# D1H.pdf register map
Vendor: Allwinner; Series: D1H.pdf; File version: 0.1
CPU: XuanTie C906 RISC-V CPU 0, little endian, MPU, FPU, double-precision FPU, 0 interrupt priority bits
Registers are 32-bit, read-write, reset 0x0 unless marked. A register's access mark holds for its fields unless they carry their own. Offsets are from the block's base; [hi:lo] are bit positions; 'fields as' and 'values as' point back to an identical list.

## CCU (part 1 of 2)
Base 0x02001000
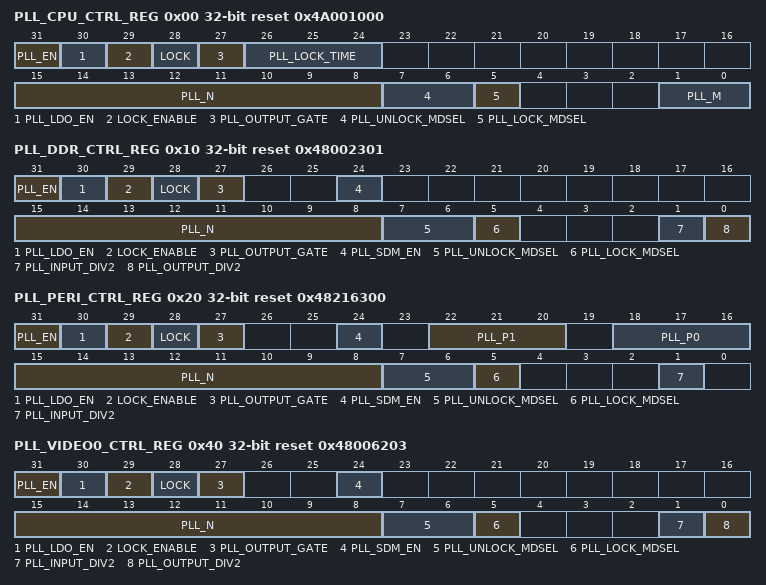
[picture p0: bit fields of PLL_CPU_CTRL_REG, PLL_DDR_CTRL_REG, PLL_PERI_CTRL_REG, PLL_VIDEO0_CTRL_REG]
0x00 PLL_CPU_CTRL_REG reset 0x4A001000 — PLL_CPU Control Register
  [31] PLL_EN — PLL Enable 0: Disable 1: Enable PLL_CPU= InputFreq*N.
    0=Disable; 1=Enable PLL_CPU= InputFreq*N
  [30] PLL_LDO_EN — LDO Enable 0: Disable 1: Enable
    0=Disable; 1=Enable
  [29] LOCK_ENABLE — Lock Enable 0: Disable 1: Enable
    0=Disable; 1=Enable
  [28] LOCK ro — PLL Lock Status 0: Unlocked 1: Locked (It indicates that the PLL has been stable.)
    0=Unlocked; 1=Locked (It indicates that the PLL has been stable.)
  [27] PLL_OUTPUT_GATE — PLL Output Gating Enable 0: Disable 1: Enable The bit is used to control the output enable of the PLL.
    0=Disable; 1=Enable The bit is used to control the output enable of the PLL
  [26:24] PLL_LOCK_TIME — PLL Lock Time The bit indicates the step amplitude from one frequency to another.
  [15:8] PLL_N — PLL N N= PLL_N +1 PLL_N is from 0 to 254. In application, PLL_N shall be more than or equal to 12.
  [7:6] PLL_UNLOCK_MDSEL — PLL Unlock Level 00: 21-29 Clock Cycles 01: 22-28 Clock Cycles 1X: 20-30 Clock Cycles
    0=_21_minus_29 (21-29 Clock Cycles); 1=_22_minus_28 (22-28 Clock Cycles)
  [5] PLL_LOCK_MDSEL — PLL Lock Level 0: 24-26 Clock Cycles 1: 23-27 Clock Cycles
    0=_24_minus_26 (24-26 Clock Cycles); 1=_23_minus_27 (23-27 Clock Cycles)
  [1:0] PLL_M — PLL_M M = PLL_FACTOR_M + 1 PLL_FACTOR_M is from 0 to 3.
0x10 PLL_DDR_CTRL_REG reset 0x48002301 — PLL_DDR Control Register
  [31] PLL_EN — 0: Disable 1: Enable PLL_DDR = InputFreq*N/M1/M0.
    0=Disable; 1=Enable PLL_DDR = InputFreq*N/M1/M0
  [30] PLL_LDO_EN — LDO ENABLE 0: Disable 1: Enable
    0=Disable; 1=Enable
  [29] LOCK_ENABLE — Lock Enable 0: Disable 1: Enable
    0=Disable; 1=Enable
  [28] LOCK ro — PLL Lock 0: Unlocked 1: Locked (It indicates that the PLL has been stable.)
    values as PLL_CPU_CTRL_REG.LOCK
  [27] PLL_OUTPUT_GATE — PLL Output Gating Enable 0: Disable 1: Enable The bit is used to control the output enable of the PLL.
    values as PLL_CPU_CTRL_REG.PLL_OUTPUT_GATE
  [24] PLL_SDM_EN — PLL SDM Enable 0: Disable 1: Enable
    0=Disable; 1=Enable
  [15:8] PLL_N — PLL N N= PLL_N +1 PLL_N is from 0 to 254. In application, PLL_N shall be more than or equal to 12.
  [7:6] PLL_UNLOCK_MDSEL — PLL Unlock Level 00: 21-29 Clock Cycles 01: 22-28 Clock Cycles 1X: 20-30 Clock Cycles
    values as PLL_CPU_CTRL_REG.PLL_UNLOCK_MDSEL
  [5] PLL_LOCK_MDSEL — PLL Lock Level 0: 24-26 Clock Cycles 1: 23-27 Clock Cycles
    values as PLL_CPU_CTRL_REG.PLL_LOCK_MDSEL
  [1] PLL_INPUT_DIV2 — PLL Input Div M1 M1=PLL_INPUT_DIV2 + 1 PLL_INPUT_DIV2 is from 0 to 1.
  [0] PLL_OUTPUT_DIV2 — PLL Output Div M0 M0=PLL_OUTPUT_DIV2 + 1 PLL_OUTPUT_DIV2 is from 0 to 1.
0x20 PLL_PERI_CTRL_REG reset 0x48216300 — PLL_PERI Control Register
  [31] PLL_EN — PLL Enable 0: Disable 1: Enable PLL_PERI(2X) = 24 MHz*N/M/P0 PLL_PERI(1X) = 24 MHz*N/M/P0/2 PLL_PERI(800M) = 24 MHz*N/M/P1. When the crystal oscillator is 24 MHz, the default frequency of PLL_PERI(2X) is 1.2 GHz, the default frequency of PLL_PERI(1X) is 600 MHz, and the default frequency of PLL_PERI(800M) is 800 MHz.
    0=Disable; 1=Enable PLL_PERI(2X) = 24 MHz*N/M/P0 PLL_PERI(1X) = 24 MHz*N/M/P0/2 PLL_PERI(800M) = 24 MHz*N/M/P1. When the crystal oscillator is 24 MHz, the default frequency of PLL_PERI(2X) is 1.2 GHz, the default frequency of PLL_PERI(1X) is 600 MHz, and the default frequency of PLL_PERI(800M) is 800 MHz.
  [30] PLL_LDO_EN — LDO Enable 0: Disable 1: Enable
    0=Disable; 1=Enable
  [29] LOCK_ENABLE — Lock Enable 0: Disable 1: Enable
    0=Disable; 1=Enable
  [28] LOCK ro — PLL Lock 0: Unlocked 1: Locked (It indicates that the PLL has been stable.)
    values as PLL_CPU_CTRL_REG.LOCK
  [27] PLL_OUTPUT_GATE — PLL Output Gating Enable 0: Disable 1: Enable The bit is used to control the output enable of PLL.
    0=Disable; 1=Enable The bit is used to control the output enable of PLL
  [24] PLL_SDM_EN — PLL SDM Enable 0: Disable 1: Enable Enable spread spectrum and decimal division.
    0=Disable; 1=Enable Enable spread spectrum and decimal division
  [22:20] PLL_P1 — PLL Output Div P1 P1=PLL_OUTPUT_DIV_P1 + 1 PLL_OUTPUT_DIV_P1 is from 0 to 7.
  [18:16] PLL_P0 — PLL Output Div P0 P0=PLL_OUTPUT_DIV_P0 + 1 PLL_OUTPUT_DIV_P0 is from 0 to 7.
  [15:8] PLL_N — PLL N N= PLL_N +1 PLL_N is from 0 to 254. In application, PLL_N shall be more than or equal to 12.
  [7:6] PLL_UNLOCK_MDSEL — PLL Unlock Level 00: 21-29 Clock Cycles 01: 22-28 Clock Cycles 1X: 20-30 Clock Cycles
    values as PLL_CPU_CTRL_REG.PLL_UNLOCK_MDSEL
  [5] PLL_LOCK_MDSEL — PLL Lock Level 0: 24-26 Clock Cycles 1: 23-27 Clock Cycles
    values as PLL_CPU_CTRL_REG.PLL_LOCK_MDSEL
  [1] PLL_INPUT_DIV2 — PLL Input Div M M1=PLL_INPUT_DIV2 + 1 PLL_INPUT_DIV2 is from 0 to 1.
0x40 PLL_VIDEO0_CTRL_REG reset 0x48006203 — PLL_VIDEO0 Control Register
  [31] PLL_EN — PLL Enable 0: Disable 1: Enable For application, PLL_VIDEO0(4X)=InputFreq *N/M. PLL_VIDEO0(2X)= InputFreq *N/M/2. PLL_VIDEO0(1X)= InputFreq *N/M/4. When the HOSC is 24 MHz, the default frequency of PLL_VIDEO0(4X) is 1188 MHz.
    0=Disable; 1=Enable For application, PLL_VIDEO0(4X)=InputFreq *N/M. PLL_VIDEO0(2X)= InputFreq *N/M/2. PLL_VIDEO0(1X)= InputFreq *N/M/4. When the HOSC is 24 MHz, the default frequency of PLL_VIDEO0(4X) is 1188 MHz.
  [30] PLL_LDO_EN — LDO Enable 0: Disable 1: Enable
    0=Disable; 1=Enable
  [29] LOCK_ENABLE — Lock Enable 0: Disable 1: Enable
    0=Disable; 1=Enable
  [28] LOCK ro — PLL Lock 0: Unlocked 1: Locked (It indicates that the PLL has been stable.)
    values as PLL_CPU_CTRL_REG.LOCK
  [27] PLL_OUTPUT_GATE — PLL Output Gating Enable 0: Disable 1: Enable The bit is used to control the output enable of PLL.
    values as PLL_PERI_CTRL_REG.PLL_OUTPUT_GATE
  [24] PLL_SDM_EN — PLL SDM Enable 0: Disable 1: Enable
    0=Disable; 1=Enable
  [15:8] PLL_N — PLL N N= PLL_N +1 PLL_N is from 0 to 254. In application, PLL_N shall be more than or equal to 12.
  [7:6] PLL_UNLOCK_MDSEL — PLL Unlock Level 00: 21-29 Clock Cycles 01: 22-28 Clock Cycles 1X: 20-30 Clock Cycles
    values as PLL_CPU_CTRL_REG.PLL_UNLOCK_MDSEL
  [5] PLL_LOCK_MDSEL — PLL Lock Level 0: 24-26 Clock Cycles 1: 23-27 Clock Cycles
    values as PLL_CPU_CTRL_REG.PLL_LOCK_MDSEL
  [1] PLL_INPUT_DIV2 — PLL Input Div M M1=PLL_INPUT_DIV_M + 1 PLL_INPUT_DIV_M is from 0 to 1.
  [0] PLL_OUTPUT_DIV2 — PLL Output Div D (The factor is only for testing) M0=PLL_OUTPUT_DIV_D + 1 PLL_OUTPUT_DIV_D is from 0 to 1. For test, PLL_VIDEO0(4X) =24MHz*N/M/D
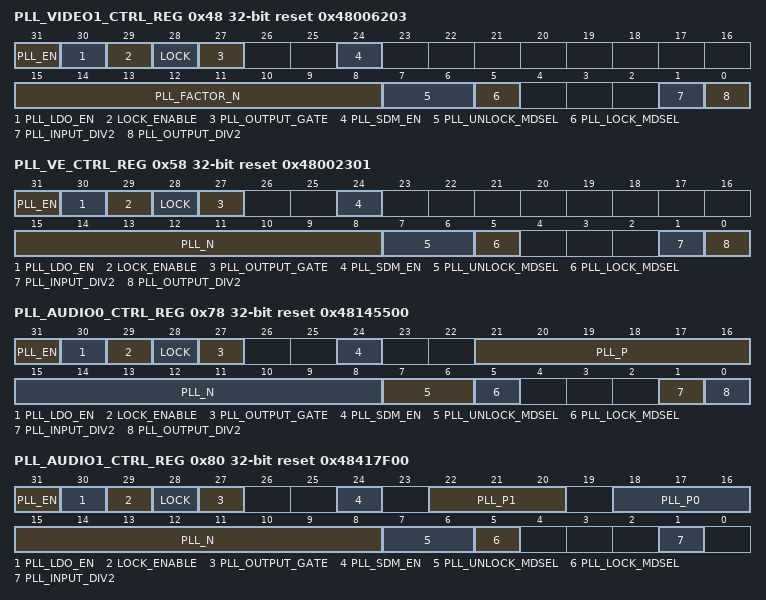
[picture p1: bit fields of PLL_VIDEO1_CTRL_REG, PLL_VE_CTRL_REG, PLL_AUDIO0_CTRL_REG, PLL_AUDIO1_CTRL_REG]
0x48 PLL_VIDEO1_CTRL_REG reset 0x48006203 — PLL_VIDEO1 Control Register
  [31] PLL_EN — PLL Enable 0: Disable 1: Enable For application, PLL_VIDEO1(4X)=InputFreq *N/M. PLL_VIDEO1(2X)= InputFreq *N/M/2. PLL_VIDEO1(1X)= InputFreq *N/M/4. When the HOSC is 24 MHz, the default frequency of PLL_VIDEO1(4X) is 1188 MHz.
    0=Disable; 1=Enable For application, PLL_VIDEO1(4X)=InputFreq *N/M. PLL_VIDEO1(2X)= InputFreq *N/M/2. PLL_VIDEO1(1X)= InputFreq *N/M/4. When the HOSC is 24 MHz, the default frequency of PLL_VIDEO1(4X) is 1188 MHz.
  [30] PLL_LDO_EN — LDO Enable 0: Disable 1: Enable
    0=Disable; 1=Enable
  [29] LOCK_ENABLE — Lock Enable 0: Disable 1: Enable
    0=Disable; 1=Enable
  [28] LOCK ro — PLL Lock 0: Unlocked 1: Locked (It indicates that the PLL has been stable.)
    values as PLL_CPU_CTRL_REG.LOCK
  [27] PLL_OUTPUT_GATE — PLL Output Gating Enable 0: Disable 1: Enable The bit is used to control the output enable of PLL.
    values as PLL_PERI_CTRL_REG.PLL_OUTPUT_GATE
  [24] PLL_SDM_EN — PLL SDM Enable 0: Disable 1: Enable
    0=Disable; 1=Enable
  [15:8] PLL_FACTOR_N — PLL FACTOR N N= PLL_FACTOR_N +1 PLL_FACTOR_N is from 0 to 254. In application, PLL_FACTOR_N shall be more than or equal to 12.
  [7:6] PLL_UNLOCK_MDSEL — PLL Unlock Level 00: 21-29 Clock Cycles 01: 22-28 Clock Cycles 1X: 20-30 Clock Cycles
    values as PLL_CPU_CTRL_REG.PLL_UNLOCK_MDSEL
  [5] PLL_LOCK_MDSEL — PLL Lock Level 0: 24-26 Clock Cycles 1: 23-27 Clock Cycles
    values as PLL_CPU_CTRL_REG.PLL_LOCK_MDSEL
  [1] PLL_INPUT_DIV2 — PLL Input Div M M1=PLL_INPUT_DIV_M + 1 PLL_INPUT_DIV_M is from 0 to 1.
  [0] PLL_OUTPUT_DIV2 — PLL Output Div D.(The factor is only for testing) M0=PLL_OUTPUT_DIV_D + 1 PLL_OUTPUT_DIV_D is from 0 to 1. For test, PLL_VIDEO1(4X) =24MHz*N/M/D
0x58 PLL_VE_CTRL_REG reset 0x48002301 — PLL_VE Control Register
  [31] PLL_EN — PLL Enable 0: Disable 1: Enable PLL_VE = InputFreq*N/M1/M0. When the HOSC is 24 MHz, the default frequency of PLL_VE is 432 MHz.
    0=Disable; 1=Enable PLL_VE = InputFreq*N/M1/M0. When the HOSC is 24 MHz, the default frequency of PLL_VE is 432 MHz.
  [30] PLL_LDO_EN — LDO Enable 0: Disable 1: Enable
    0=Disable; 1=Enable
  [29] LOCK_ENABLE — Lock Enable 0: Disable 1: Enable
    0=Disable; 1=Enable
  [28] LOCK ro — PLL Lock 0: Unlocked 1: Locked (It indicates that the PLL has been stable.)
    values as PLL_CPU_CTRL_REG.LOCK
  [27] PLL_OUTPUT_GATE — PLL Output Gating Enable 0: Disable 1: Enable The bit is used to control the output enable of PLL.
    values as PLL_PERI_CTRL_REG.PLL_OUTPUT_GATE
  [24] PLL_SDM_EN — PLL SDM Enable 0: Disable 1: Enable
    0=Disable; 1=Enable
  [15:8] PLL_N — PLL N N= PLL_N +1 PLL_N is from 0 to 254. In application, PLL_N shall be more than or equal to 12.
  [7:6] PLL_UNLOCK_MDSEL — PLL Unlock Level 00: 21-29 Clock Cycles 01: 22-28 Clock Cycles 1X: 20-30 Clock Cycles
    values as PLL_CPU_CTRL_REG.PLL_UNLOCK_MDSEL
  [5] PLL_LOCK_MDSEL — PLL Lock Level 0: 24-26 Clock Cycles 1: 23-27 Clock Cycles
    values as PLL_CPU_CTRL_REG.PLL_LOCK_MDSEL
  [1] PLL_INPUT_DIV2 — PLL Input Div M1 M1=PLL_INPUT_DIV2 + 1 PLL_INPUT_DIV2 is from 0 to 1.
  [0] PLL_OUTPUT_DIV2 — PLL Output Div M0 M0=PLL_OUTPUT_DIV2 + 1 PLL_OUTPUT_DIV2 is from 0 to 1.
0x78 PLL_AUDIO0_CTRL_REG reset 0x48145500 — PLL_AUDIO0 Control Register
  [31] PLL_EN — PLL Enable 0: Disable 1: Enable PLL_AUDIO0(4X) = 24MHz*N/M1/M0/P PLL_AUDIO0(2X) = (24MHz*N/M1/M0)/P/2 PLL_AUDIO0(1X) = (24MHz*N/M1/M0)/P/4 The working frequency range of 24MHz*N/M0/M1 is from 180 MHz to 3.0 GHz. The default frequency of PLL_AUDIO0(1X) is 24.5714 MHz.
    0=Disable; 1=Enable PLL_AUDIO0(4X) = 24MHz*N/M1/M0/P PLL_AUDIO0(2X) = (24MHz*N/M1/M0)/P/2 PLL_AUDIO0(1X) = (24MHz*N/M1/M0)/P/4 The working frequency range of 24MHz*N/M0/M1 is from 180 MHz to 3.0 GHz. The default frequency of PLL_AUDIO0(1X) is 24.5714 MHz.
  [30] PLL_LDO_EN — LDO Enable 0: Disable 1: Enable
    0=Disable; 1=Enable
  [29] LOCK_ENABLE — Lock Enable 0: Disable 1: Enable
    0=Disable; 1=Enable
  [28] LOCK ro — PLL Lock 0: Unlocked 1: Locked (It indicates that the PLL has been stable.)
    values as PLL_CPU_CTRL_REG.LOCK
  [27] PLL_OUTPUT_GATE — 0: Disable 1: Enable The bit is used to control the output enable of PLL.
    values as PLL_PERI_CTRL_REG.PLL_OUTPUT_GATE
  [24] PLL_SDM_EN — PLL SDM Enable 0: Disable 1: Enable Enable spread spectrum and decimal division.
    values as PLL_PERI_CTRL_REG.PLL_SDM_EN
  [21:16] PLL_P — PLL Post-div P P= PLL_POST_DIV_P +1 PLL_POST_DIV_P is from 0 to 63.
  [15:8] PLL_N — PLL N N= PLL_N +1 PLL_N is from 0 to 254. In application, PLL_N shall be more than or equal to 12.
  [7:6] PLL_UNLOCK_MDSEL — PLL Unlock Level 00: 21-29 Clock Cycles 01: 22-28 Clock Cycles 1X: 20-30 Clock Cycles
    values as PLL_CPU_CTRL_REG.PLL_UNLOCK_MDSEL
  [5] PLL_LOCK_MDSEL — PLL Lock Level 0: 24-26 Clock Cycles 1: 23-27 Clock Cycles
    values as PLL_CPU_CTRL_REG.PLL_LOCK_MDSEL
  [1] PLL_INPUT_DIV2 — PLL Input Div M1 M1=PLL_INPUT_DIV2 + 1 PLL_INPUT_DIV2 is from 0 to 1.
  [0] PLL_OUTPUT_DIV2 — PLL Output Div M0 M0=PLL_OUTPUT_DIV2 + 1 PLL_OUTPUT_DIV2 is from 0 to 1.
0x80 PLL_AUDIO1_CTRL_REG reset 0x48417F00 — PLL_AUDIO1 Control Register
  [31] PLL_EN — PLL Enable 0: Disable 1: Enable PLL_AUDIO1 = 24MHz*N/M PLL_AUDIO1(DIV2) = 24MHz*N/M/P0 PLL_AUDIO1(DIV5) = 24MHz*N/M/P1 The working frequency range of 24 MHz/M*N is from 180 MHz to 3.5 GHz. The default frequency of PLL_AUDIO1 is 3072 MHz. The default frequency of PLL_AUDIO1(DIV2) is 1536 MHz. The default frequency of PLL_AUDIO1(DIV5) is 614.4 MHz (24.576 MHz*25).
    0=Disable; 1=Enable PLL_AUDIO1 = 24MHz*N/M PLL_AUDIO1(DIV2) = 24MHz*N/M/P0 PLL_AUDIO1(DIV5) = 24MHz*N/M/P1 The working frequency range of 24 MHz/M*N is from 180 MHz to 3.5 GHz. The default frequency of PLL_AUDIO1 is 3072 MHz. The default frequency of PLL_AUDIO1(DIV2) is 1536 MHz. The default frequency of PLL_AUDIO1(DIV5) is 614.4 MHz (24.576 MHz*25).
  [30] PLL_LDO_EN — LDO Enable 0: Disable 1: Enable
    0=Disable; 1=Enable
  [29] LOCK_ENABLE — Lock Enable 0: Disable 1: Enable
    0=Disable; 1=Enable
  [28] LOCK ro — 0: Unlocked 1: Locked (It indicates that the PLL has been stable.)
    values as PLL_CPU_CTRL_REG.LOCK
  [27] PLL_OUTPUT_GATE — 0: Disable 1: Enable The bit is used to control the output enable of PLL.
    values as PLL_PERI_CTRL_REG.PLL_OUTPUT_GATE
  [24] PLL_SDM_EN — 0: Disable 1: Enable Enable spread spectrum and decimal division.
    values as PLL_PERI_CTRL_REG.PLL_SDM_EN
  [22:20] PLL_P1 — PLL Output Div P1 P1=PLL_OUTPUT_DIV_P1 + 1 PLL_OUTPUT_DIV_P1 is from 0 to 7.
  [18:16] PLL_P0 — PLL Output Div P0 P0=PLL_OUTPUT_DIV_P0 + 1 PLL_OUTPUT_DIV_P0 is from 0 to 7.
  [15:8] PLL_N — PLL N N= PLL_N +1 PLL_N is from 0 to 254. In application, PLL_N shall be more than or equal to 12.
  [7:6] PLL_UNLOCK_MDSEL — PLL Unlock Level 00: 21-29 Clock Cycles 01: 22-28 Clock Cycles 1X: 20-30 Clock Cycles
    values as PLL_CPU_CTRL_REG.PLL_UNLOCK_MDSEL
  [5] PLL_LOCK_MDSEL — PLL Lock Level 0: 24-26 Clock Cycles 1: 23-27 Clock Cycles
    values as PLL_CPU_CTRL_REG.PLL_LOCK_MDSEL
  [1] PLL_INPUT_DIV2 — PLL Input Div M M=PLL_INPUT_DIV_M + 1 PLL_INPUT_DIV_M is from 0 to 1.
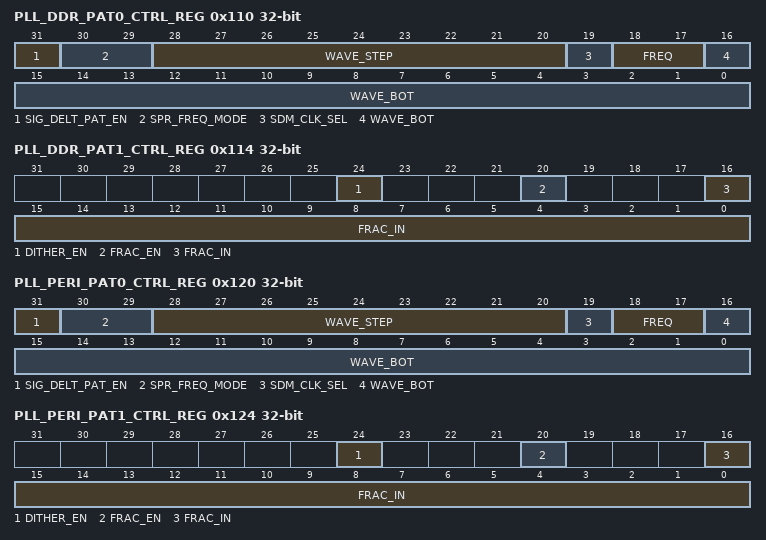
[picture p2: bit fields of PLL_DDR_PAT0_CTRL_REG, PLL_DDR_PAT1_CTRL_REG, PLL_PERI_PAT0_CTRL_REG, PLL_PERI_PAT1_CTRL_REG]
0x110 PLL_DDR_PAT0_CTRL_REG — PLL_DDR Pattern0 Control Register
  [31] SIG_DELT_PAT_EN — Sigma-Delta Pattern Enable
  [30:29] SPR_FREQ_MODE — Spread Frequency Mode 00: DC=0 01: DC=1 10: Triangular(1-bit) 11: Triangular(n-bit)
    0=DC_equals_0 (DC=0); 1=DC_equals_1 (DC=1); 2=Triangular_openingparen_1_bit_closingparen_ (Triangular(1-bit)); 3=Triangular_openingparen_n_bit_closingparen_ (Triangular(n-bit))
  [28:20] WAVE_STEP
  [19] SDM_CLK_SEL — SDM Clock Select 0: 24 MHz 1: 12 MHz
    0=24 MHz; 1=12 MHz
  [18:17] FREQ — Frequency 00: 31.5 kHz 01: 32 kHz 10: 32.5 kHz 11: 33 kHz
    0=_31_point_5_kHz (31.5 kHz); 1=_32_kHz; 2=_32_point_5_kHz (32.5 kHz); 3=_33_kHz
  [16:0] WAVE_BOT — Wave Bottom
0x114 PLL_DDR_PAT1_CTRL_REG — PLL_DDR Pattern1 Control Register
  [24] DITHER_EN — Dither Enable
  [20] FRAC_EN — Fraction Enable
  [16:0] FRAC_IN — Fraction In
0x120 PLL_PERI_PAT0_CTRL_REG — PLL_PERI Pattern0 Control Register
  fields as PLL_DDR_PAT0_CTRL_REG
0x124 PLL_PERI_PAT1_CTRL_REG — PLL_PERI Pattern1 Control Register
  fields as PLL_DDR_PAT1_CTRL_REG
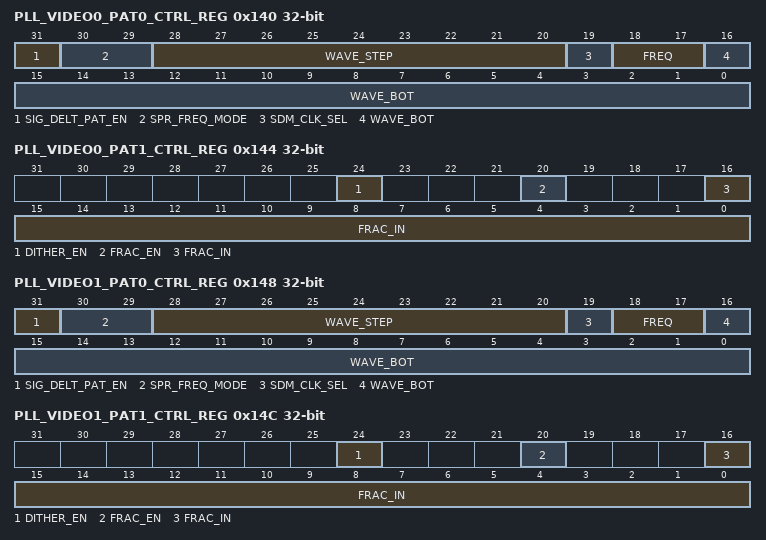
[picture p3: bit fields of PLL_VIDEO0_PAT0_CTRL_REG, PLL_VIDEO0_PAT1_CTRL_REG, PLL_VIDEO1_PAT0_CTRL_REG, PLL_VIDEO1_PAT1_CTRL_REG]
0x140 PLL_VIDEO0_PAT0_CTRL_REG — PLL_VIDEO0 Pattern0 Control Register
  fields as PLL_DDR_PAT0_CTRL_REG
0x144 PLL_VIDEO0_PAT1_CTRL_REG — PLL_VIDEO0 Pattern1 Control Register
  fields as PLL_DDR_PAT1_CTRL_REG
0x148 PLL_VIDEO1_PAT0_CTRL_REG — PLL_VIDEO1 Pattern0 Control Register
  fields as PLL_DDR_PAT0_CTRL_REG
0x14C PLL_VIDEO1_PAT1_CTRL_REG — PLL_VIDEO1 Pattern1 Control Register
  fields as PLL_DDR_PAT1_CTRL_REG
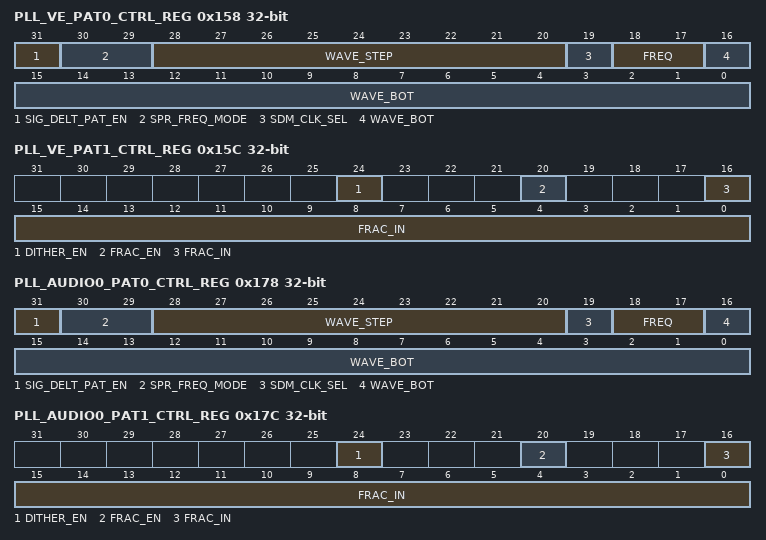
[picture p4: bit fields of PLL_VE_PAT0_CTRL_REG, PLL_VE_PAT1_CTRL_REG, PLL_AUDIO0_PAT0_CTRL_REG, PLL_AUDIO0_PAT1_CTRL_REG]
0x158 PLL_VE_PAT0_CTRL_REG — PLL_VE Pattern0 Control Register
  fields as PLL_DDR_PAT0_CTRL_REG
0x15C PLL_VE_PAT1_CTRL_REG — PLL_VE Pattern1 Control Register
  fields as PLL_DDR_PAT1_CTRL_REG
0x178 PLL_AUDIO0_PAT0_CTRL_REG — PLL_AUDIO0 Pattern0 Control Register
  fields as PLL_DDR_PAT0_CTRL_REG
0x17C PLL_AUDIO0_PAT1_CTRL_REG — PLL_AUDIO0 Pattern1 Control Register
  fields as PLL_DDR_PAT1_CTRL_REG
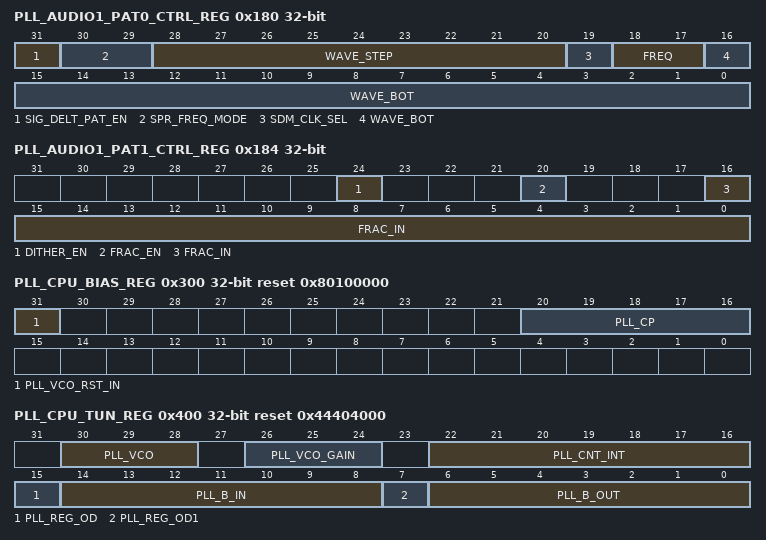
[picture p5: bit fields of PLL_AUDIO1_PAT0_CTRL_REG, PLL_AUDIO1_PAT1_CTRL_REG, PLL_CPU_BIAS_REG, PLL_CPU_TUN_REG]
0x180 PLL_AUDIO1_PAT0_CTRL_REG — PLL_AUDIO1 Pattern0 Control Register
  fields as PLL_DDR_PAT0_CTRL_REG
0x184 PLL_AUDIO1_PAT1_CTRL_REG — PLL_AUDIO1 Pattern1 Control Register
  fields as PLL_DDR_PAT1_CTRL_REG
0x300 PLL_CPU_BIAS_REG reset 0x80100000 — PLL_CPU Bias Register
  [31] PLL_VCO_RST_IN — VCO reset in
  [20:16] PLL_CP — PLL current bias control
0x310 PLL_DDR_BIAS_REG reset 0x30000 — PLL_DDR Bias Register
  [20:16] PLL_CP — PLL bias control
0x320 PLL_PERI_BIAS_REG reset 0x30000 — PLL_PERI Bias Register
  [20:16] PLL_CP — PLL bias control
0x340 PLL_VIDEO0_BIAS_REG reset 0x30000 — PLL_VIDEO0 Bias Register
  [20:16] PLL_CP — PLL bias control
0x348 PLL_VIDEO1_BIAS_REG reset 0x30000 — PLL_VIDEO1 Bias Register
  [20:16] PLL_CP — PLL bias control
0x358 PLL_VE_BIAS_REG reset 0x30000 — PLL_VE Bias Register
  [20:16] PLL_CP — PLL bias control
0x378 PLL_AUDIO0_BIAS_REG reset 0x30000 — PLL_AUDIO0 Bias Register
  [20:16] PLL_CP — PLL bias control
0x380 PLL_AUDIO1_BIAS_REG reset 0x30000 — PLL_AUDIO1 Bias Register
  [20:16] PLL_CP — PLL bias control
0x400 PLL_CPU_TUN_REG reset 0x44404000 — PLL_CPU Tuning Register
  [30:28] PLL_VCO — VCO range control
  [26:24] PLL_VCO_GAIN — KVCO gain control
  [22:16] PLL_CNT_INT — Counter initial control
  [15] PLL_REG_OD — PLL-REG-OD0 for verify
  [14:8] PLL_B_IN — PLL-B-IN [6:0] for verify
  [7] PLL_REG_OD1 — PLL-REG-OD1 for verify
  [6:0] PLL_B_OUT ro — PLL-B-OUT [6:0] for verify
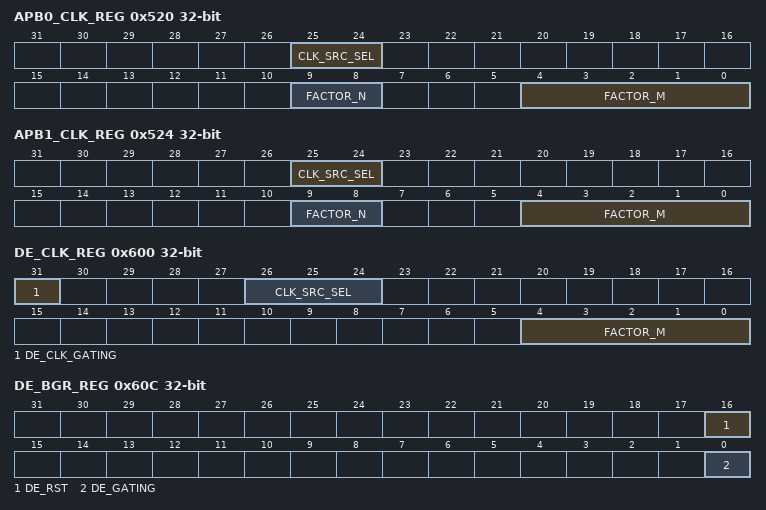
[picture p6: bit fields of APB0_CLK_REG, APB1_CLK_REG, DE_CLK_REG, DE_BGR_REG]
0x520 APB0_CLK_REG — APB0 Clock Register
  [25:24] CLK_SRC_SEL — Clock Source Select 00: HOSC 01: CLK32K 10: PSI_CLK 11: PLL_PERI(1X) APB0_CLK = Clock Source/M/N.
    0=HOSC; 1=CLK32K; 2=PSI_CLK; 3=PLL_PERI_openingparen_1X_closingparen_ (PLL_PERI(1X) APB0_CLK = Clock Source/M/N.)
  [9:8] FACTOR_N — Factor N 00: 1 01: 2 10: 4 11: 8
    0=_1; 1=_2; 2=_4; 3=_8
  [4:0] FACTOR_M — Factor M M = FACTOR_M+1 FACTOR_M is from 0 to 31.
0x524 APB1_CLK_REG — APB1 Clock Register
  [25:24] CLK_SRC_SEL — Clock Source Select 00: HOSC 01: CLK32K 10: PSI_CLK 11: PLL_PERI(1X) APB1_CLK = Clock Source/M/N.
    0=HOSC; 1=CLK32K; 2=PSI_CLK; 3=PLL_PERI_openingparen_1X_closingparen_ (PLL_PERI(1X) APB1_CLK = Clock Source/M/N.)
  [9:8] FACTOR_N — Factor N 00: 1 01: 2 10: 4 11: 8
    0=_1; 1=_2; 2=_4; 3=_8
  [4:0] FACTOR_M — Factor M M = FACTOR_M+1 FACTOR_M is from 0 to 31.
0x540 MBUS_CLK_REG reset 0x40000000 — MBUS Clock Register
  [30] MBUS_RST — MBUS Reset 0: Assert 1: De-assert
    0=Assert; 1=deassert
0x600 DE_CLK_REG — DE Clock Register
  [31] DE_CLK_GATING — Gating Clock 0: Clock is OFF 1: Clock is ON DE_CLK = Clock Source/M.
    0=OFF (Clock is OFF); 1=ON (Clock is ON DE_CLK = Clock Source/M.)
  [26:24] CLK_SRC_SEL — Clock Source Select 000: PLL_PERI(2X) 001: PLL_VIDEO0(4X) 010: PLL_VIDEO1(4X) 011: PLL_AUDIO1(DIV2)
    0=PLL_PERI_openingparen_2X_closingparen_ (PLL_PERI(2X)); 1=PLL_VIDEO0_openingparen_4X_closingparen_ (PLL_VIDEO0(4X)); 2=PLL_VIDEO1_openingparen_4X_closingparen_ (PLL_VIDEO1(4X)); 3=PLL_AUDIO1_openingparen_DIV2_closingparen_ (PLL_AUDIO1(DIV2))
  [4:0] FACTOR_M — Factor M M= FACTOR_M +1 FACTOR_M is from 0 to 31.
0x60C DE_BGR_REG — DE Bus Gating Reset Register
  [16] DE_RST — DE Reset 0: Assert 1: De-assert
    0=Assert; 1=deassert
  [0] DE_GATING — DE Gating Clock 0: Mask 1: Pass
    0=Mask; 1=Pass
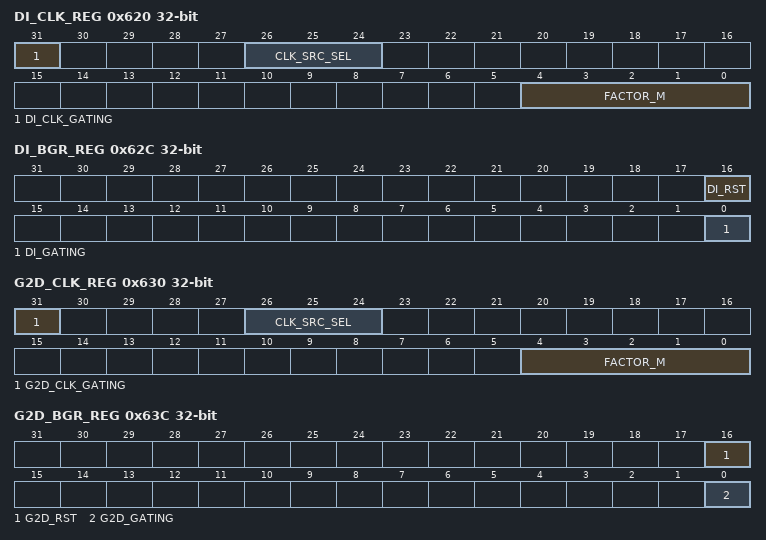
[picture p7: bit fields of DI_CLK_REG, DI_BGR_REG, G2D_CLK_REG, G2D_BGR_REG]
0x620 DI_CLK_REG — DI Clock Register
  [31] DI_CLK_GATING — Gating Clock 0: Clock is OFF 1: Clock is ON DI_CLK = Clock Source/M.
    0=OFF (Clock is OFF); 1=ON (Clock is ON DI_CLK = Clock Source/M.)
  [26:24] CLK_SRC_SEL — Clock Source Select 000: PLL_PERI(2X) 001: PLL_VIDEO0(4X) 010: PLL_VIDEO1(4X) 011: PLL_AUDIO1(DIV2)
    values as DE_CLK_REG.CLK_SRC_SEL
  [4:0] FACTOR_M — Factor M M = FACTOR_M +1 FACTOR_M is from 0 to 31.
0x62C DI_BGR_REG — DI Bus Gating Reset Register
  [16] DI_RST — DI Reset 0: Assert 1: De-assert
    0=Assert; 1=deassert
  [0] DI_GATING — DI Gating Clock 0: Mask 1: Pass
    0=Mask; 1=Pass
0x630 G2D_CLK_REG — G2D Clock Register
  [31] G2D_CLK_GATING — Gating Clock 0: Clock is OFF 1: Clock is ON G2D_CLK = Clock Source/M.
    0=OFF (Clock is OFF); 1=ON (Clock is ON G2D_CLK = Clock Source/M.)
  [26:24] CLK_SRC_SEL — Clock Source Select 000: PLL_PERI(2X) 001: PLL_VIDEO0(4X) 010: PLL_VIDEO1(4X) 011: PLL_AUDIO1(DIV2)
    values as DE_CLK_REG.CLK_SRC_SEL
  [4:0] FACTOR_M — Factor M M= FACTOR_M +1 FACTOR_M is from 0 to 31.
0x63C G2D_BGR_REG — G2D Bus Gating Reset Register
  [16] G2D_RST — G2D Reset 0: Assert 1: De-assert
    0=Assert; 1=deassert
  [0] G2D_GATING — G2D Gating Clock 0: Mask 1: Pass
    0=Mask; 1=Pass
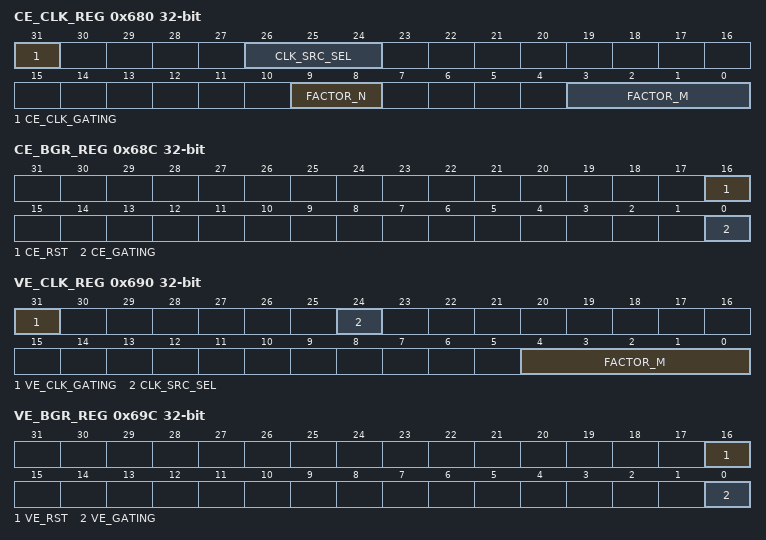
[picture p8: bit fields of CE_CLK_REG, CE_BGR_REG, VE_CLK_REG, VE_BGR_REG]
0x680 CE_CLK_REG — CE Clock Register
  [31] CE_CLK_GATING — Gating Clock 0: Clock is OFF 1: Clock is ON CE_CLK = Clock Source/M/N.
    0=OFF (Clock is OFF); 1=ON (Clock is ON CE_CLK = Clock Source/M/N.)
  [26:24] CLK_SRC_SEL — Clock Source Select 00: HOSC 01: PLL_PERI(2X) 10: PLL_PERI(1X)
  [9:8] FACTOR_N — Factor N 00: 1 01: 2 10: 4 11: 8
    0=_1; 1=_2; 2=_4; 3=_8
  [3:0] FACTOR_M — Factor M M= FACTOR_M +1 FACTOR_M is from 0 to 15.
0x68C CE_BGR_REG — CE Bus Gating Reset Register
  [16] CE_RST — CE Reset 0: Assert 1: De-assert
    0=Assert; 1=deassert
  [0] CE_GATING — CE Gating Clock 0: Mask 1: Pass
    0=Mask; 1=Pass
0x690 VE_CLK_REG — VE Clock Register
  [31] VE_CLK_GATING — Gating Clock 0: Clock is OFF 1: Clock is ON VE_CLK = Clock Source/M.
    0=OFF (Clock is OFF); 1=ON (Clock is ON VE_CLK = Clock Source/M.)
  [24] CLK_SRC_SEL — Clock Source Select 0: PLL_VE 1: PLL_PERI(2X)
    0=PLL_VE; 1=PLL_PERI_openingparen_2X_closingparen_ (PLL_PERI(2X))
  [4:0] FACTOR_M — Factor M M= FACTOR_M +1 FACTOR_M is from 0 to 31.
0x69C VE_BGR_REG — VE Bus Gating Reset Register
  [16] VE_RST — VE Reset for VE_PROT 0: Assert 1: DE-assert
    0=Assert; 1=deassert
  [0] VE_GATING — Gating Clock for VE_PROT 0: Mask 1: Pass
    0=Mask; 1=Pass
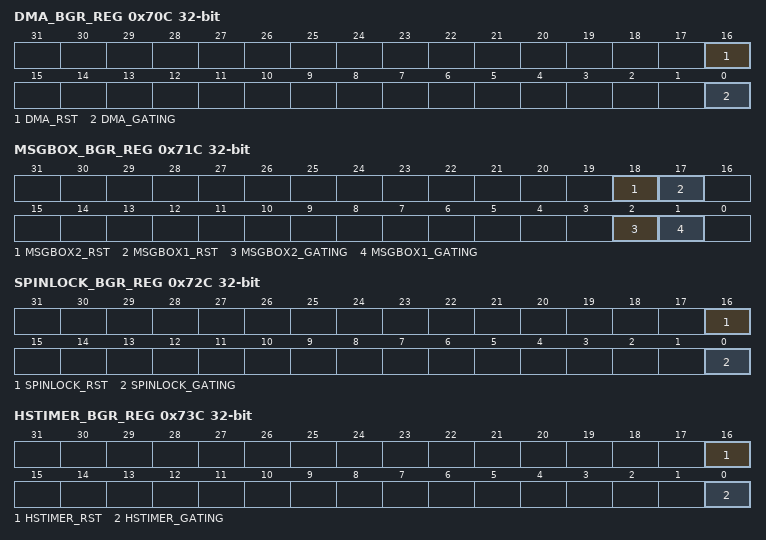
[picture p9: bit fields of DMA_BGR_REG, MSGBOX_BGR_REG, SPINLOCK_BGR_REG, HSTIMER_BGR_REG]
0x70C DMA_BGR_REG — DMA Bus Gating Reset Register
  [16] DMA_RST — DMA Reset 0: Assert 1: De-assert
    0=Assert; 1=deassert
  [0] DMA_GATING — DMA Gating Clock 0: Mask 1: Pass
    0=Mask; 1=Pass
0x71C MSGBOX_BGR_REG — MSGBOX Bus Gating Reset Register
  [18] MSGBOX2_RST — RISC-V MSGBOX Reset 0: Assert 1: De-assert
    0=Assert; 1=deassert
  [17] MSGBOX1_RST — DSP MSGBOX Reset 0: Assert 1: De-assert
    0=Assert; 1=deassert
  [2] MSGBOX2_GATING — Gating Clock for RISC-V MSGBOX 0: Mask 1: Pass
    0=Mask; 1=Pass
  [1] MSGBOX1_GATING — Gating Clock for DSP MSGBOX 0: Mask 1: Pass
    0=Mask; 1=Pass
0x72C SPINLOCK_BGR_REG — SPINLOCK Bus Gating Reset Register
  [16] SPINLOCK_RST — SPINLOCK Reset 0: Assert 1: De-assert
    0=Assert; 1=deassert
  [0] SPINLOCK_GATING — Gating Clock for SPINLOCK 0: Mask 1: Pass
    0=Mask; 1=Pass
0x73C HSTIMER_BGR_REG — HSTIMER Bus Gating Reset Register
  [16] HSTIMER_RST — HSTIMER Reset 0: Assert 1: De-assert
    0=Assert; 1=deassert
  [0] HSTIMER_GATING — Gating Clock for HSTIMER 0: Mask 1: Pass
    0=Mask; 1=Pass
0x740 AVS_CLK_REG — AVS Clock Register
  [31] AVS_CLK_GATING — Gating Clock The AVS_CLK is from HOSC. 0: Clock is OFF 1: Clock is ON
    0=OFF (Clock is OFF); 1=ON (Clock is ON)
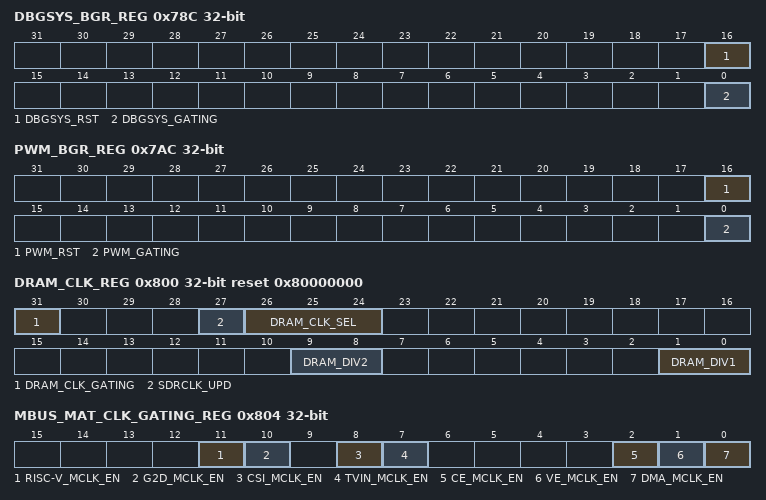
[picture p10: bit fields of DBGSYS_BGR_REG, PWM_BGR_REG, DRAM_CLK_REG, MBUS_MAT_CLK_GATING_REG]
0x78C DBGSYS_BGR_REG — DBGSYS Bus Gating Reset Register
  [16] DBGSYS_RST — DBGSYS Reset 0: Assert 1: De-assert
    0=Assert; 1=deassert
  [0] DBGSYS_GATING — Gating Clock for DBGSYS The clock of DBGSYS is from HOSC. 0: Mask 1: Pass
    0=Mask; 1=Pass
0x7AC PWM_BGR_REG — PWM Bus Gating Reset Register
  [16] PWM_RST — PWM Reset 0: Assert 1: De-assert
    0=Assert; 1=deassert
  [0] PWM_GATING — Gating Clock for PWM 0: Mask 1: Pass
    0=Mask; 1=Pass
0x7BC IOMMU_BGR_REG — IOMMU Bus Gating Reset Register
  [0] IOMMU_GATING — Gating Clock for IOMMU 0: Mask 1: Pass
    0=Mask; 1=Pass
0x800 DRAM_CLK_REG reset 0x80000000 — DRAM Clock Register
  [31] DRAM_CLK_GATING — Gating Clock DRAM_CLK = Clock Source/M/N. 0: Clock is OFF 1: Clock is ON
    0=OFF (Clock is OFF); 1=ON (Clock is ON)
  [27] SDRCLK_UPD — SDRCLK Configuration 0 Update 0: Invalid 1: Valid Setting 1 will validate the bit. It will be automatically cleared after the bit is valid. Here supports dram req/ack signal. When dram_update is set to 1, dram_clk_sel/dram_div2/dram_clk1 will be updated.
    0=Invalid; 1=Valid Setting 1 will validate the bit. It will be automatically cleared after the bit is valid. Here supports dram req/ack signal. When dram_update is set to 1, dram_clk_sel/dram_div2/dram_clk1 will be updated.
  [26:24] DRAM_CLK_SEL — Clock Source Select 00: PLL_DDR 01: PLL_AUDIO1(DIV2) 10: PLL_PERI(2X) 11: PLL_PERI(800M)
  [9:8] DRAM_DIV2 — Factor N 00: 1 01: 2 10: 4 11: 8
    0=_1; 1=_2; 2=_4; 3=_8
  [1:0] DRAM_DIV1 — Factor M M= FACTOR_M +1 FACTOR_M is from 0 to 3.
0x804 MBUS_MAT_CLK_GATING_REG — MBUS Master Clock Gating Register
  [all] fields
    0=Mask; 1=Pass
  [11] RISC-V_MCLK_EN — Gating MBUS Clock for RISC-V 0: Mask 1: Pass
  [10] G2D_MCLK_EN — Gating MBUS Clock for G2D 0: Mask 1: Pass
  [8] CSI_MCLK_EN — Gating MBUS Clock for CSI 0: Mask 1: Pass
  [7] TVIN_MCLK_EN — Gating MBUS Clock for TVIN 0: Mask 1: Pass
  [2] CE_MCLK_EN — Gating MBUS Clock for CE 0: Mask 1: Pass
  [1] VE_MCLK_EN — Gating MBUS Clock for VE 0: Mask 1: Pass
  [0] DMA_MCLK_EN — Gating MBUS Clock for DMA 0: Mask 1: Pass
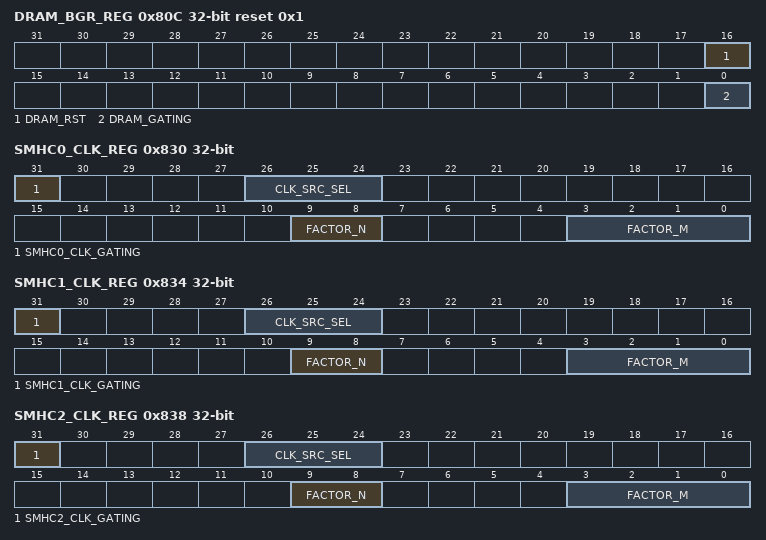
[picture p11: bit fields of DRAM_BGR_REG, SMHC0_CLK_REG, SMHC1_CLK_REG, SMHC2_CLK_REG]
0x80C DRAM_BGR_REG reset 0x1 — DRAM Bus Gating Reset Register
  [16] DRAM_RST — DRAM Reset 0: Assert 1: De-assert
    0=Assert; 1=deassert
  [0] DRAM_GATING — Gating Clock for DRAM 0: Mask 1: Pass
    0=Mask; 1=Pass
0x830 SMHC0_CLK_REG — SMHC0 Clock Register
  [31] SMHC0_CLK_GATING — Gating Clock 0: Clock is OFF 1: Clock is ON SMHC0_CLK = Clock Source/M/N.
    0=OFF (Clock is OFF); 1=ON (Clock is ON SMHC0_CLK = Clock Source/M/N.)
  [26:24] CLK_SRC_SEL — Clock Source Select 000: HOSC 001: PLL_PERI(1X) 010: PLL_PERI(2X) 011: PLL_AUDIO1(DIV2) Others: Reserved
    0=HOSC; 1=PLL_PERI_openingparen_1X_closingparen_ (PLL_PERI(1X)); 2=PLL_PERI_openingparen_2X_closingparen_ (PLL_PERI(2X)); 3=PLL_AUDIO1_openingparen_DIV2_closingparen_ (PLL_AUDIO1(DIV2))
  [9:8] FACTOR_N — Factor N 00: 1 01: 2 10: 4 11: 8
    0=_1; 1=_2; 2=_4; 3=_8
  [3:0] FACTOR_M — Factor M M = FACTOR_M +1 FACTOR_M is from 0 to 15.
0x834 SMHC1_CLK_REG — SMHC1 Clock Register
  [31] SMHC1_CLK_GATING — Gating Clock 0: Clock is OFF 1: Clock is ON SCLK = Clock Source/M/N.
    0=OFF (Clock is OFF); 1=ON (Clock is ON SCLK = Clock Source/M/N.)
  [26:24] CLK_SRC_SEL — Clock Source Select 000: HOSC 001: PLL_PERI(1X) 010: PLL_PERI(2X) 011: PLL_AUDIO1(DIV2) Others: Reserved
    values as SMHC0_CLK_REG.CLK_SRC_SEL
  [9:8] FACTOR_N — Factor N 00: 1 01: 2 10: 4 11: 8
    0=_1; 1=_2; 2=_4; 3=_8
  [3:0] FACTOR_M — Factor M M= FACTOR_M +1 FACTOR_M is from 0 to 15.
0x838 SMHC2_CLK_REG — SMHC2 Clock Register
  [31] SMHC2_CLK_GATING — Gating Clock 0: Clock is OFF 1: Clock is ON SCLK = Clock Source/M/N.
    values as SMHC1_CLK_REG.SMHC1_CLK_GATING
  [26:24] CLK_SRC_SEL — Clock Source Select 000: HOSC 001: PLL_PERI(1X) 010: PLL_PERI(2X) 011: PLL_PERI(800M) 100: PLL_AUDIO1(DIV2) Others: Reserved
    0=HOSC; 1=PLL_PERI_openingparen_1X_closingparen_ (PLL_PERI(1X)); 2=PLL_PERI_openingparen_2X_closingparen_ (PLL_PERI(2X)); 3=PLL_PERI_openingparen_800M_closingparen_ (PLL_PERI(800M)); 4=PLL_AUDIO1_openingparen_DIV2_closingparen_ (PLL_AUDIO1(DIV2))
  [9:8] FACTOR_N — Factor N 00: 1 01: 2 10: 4 11: 8
    0=_1; 1=_2; 2=_4; 3=_8
  [3:0] FACTOR_M — Factor M M= FACTOR_M +1 FACTOR_M is from 0 to 15.
